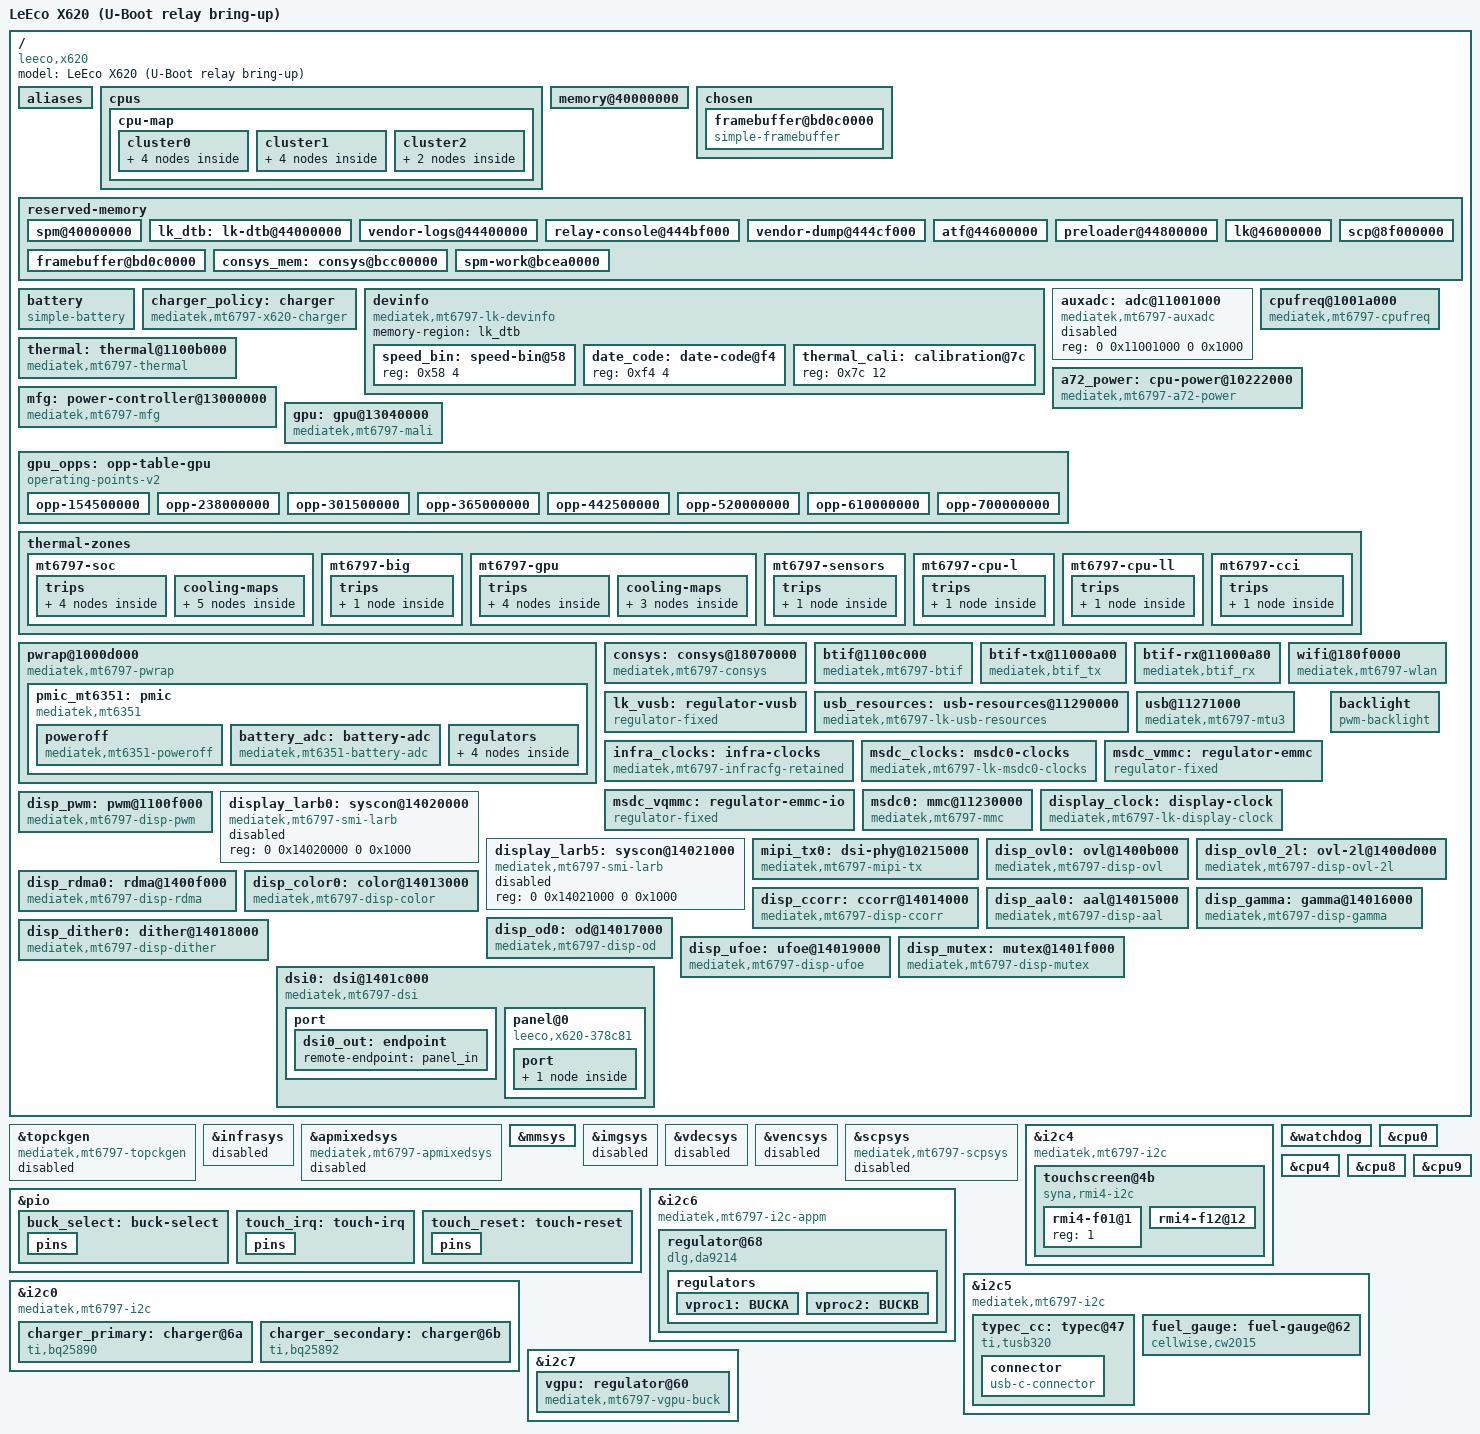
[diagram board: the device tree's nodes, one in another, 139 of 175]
// SPDX-License-Identifier: GPL-2.0-only
/dts-v1/;
#include "mt6797.dtsi"
#include <dt-bindings/clock/mt6797-clk.h>
#include <dt-bindings/gpio/gpio.h>
#include <dt-bindings/thermal/thermal.h>

/ {
	model = "LeEco X620 (U-Boot relay bring-up)";
	compatible = "leeco,x620", "mediatek,mt6797";
	aliases {
		mmc0 = &msdc0;
		i2c0 = &i2c0;
		i2c5 = &i2c5;
		i2c4 = &i2c4;
		i2c6 = &i2c6;
		i2c7 = &i2c7;
		ovl0 = &disp_ovl0;
		ovl-2l0 = &disp_ovl0_2l;
		rdma0 = &disp_rdma0;
		dsi0 = &dsi0;
		mutex0 = &disp_mutex;
	};
	cpus {
		cpu-map {
			cluster0 {
				core0 { cpu = <&cpu0>; };
				core1 { cpu = <&cpu1>; };
				core2 { cpu = <&cpu2>; };
				core3 { cpu = <&cpu3>; };
			};
			cluster1 {
				core0 { cpu = <&cpu4>; };
				core1 { cpu = <&cpu5>; };
				core2 { cpu = <&cpu6>; };
				core3 { cpu = <&cpu7>; };
			};
			cluster2 {
				core0 { cpu = <&cpu8>; };
				core1 { cpu = <&cpu9>; };
			};
		};
	};
	memory@40000000 {
		device_type = "memory";
		/* LK-populated banks from the live stock DT; firmware holes stay excluded. */
		reg = <0 0x40000000 0 0x4e000000>,
		      <0 0x8e600000 0 0x11a00000>,
		      <0 0xa0000000 0 0x12000000>,
		      <0 0xb9000000 0 0x03000000>,
		      <0 0xbcc00000 0 0x002c0000>,
		      <0 0xc0000000 0 0x40000000>;
	};
	chosen {
		#address-cells = <2>;
		#size-cells = <2>;
		ranges;
		bootargs = "console=tty0 earlycon=mt6797ram,mmio32,0x444bf000 keep_bootcon loglevel=8 ignore_loglevel printk.time=1 clk_ignore_unused pd_ignore_unused maxcpus=1 cpuidle.off=1 rdinit=/init panic=0 fsck.mode=skip fbcon=nodefer";
		framebuffer@bd0c0000 {
			compatible = "simple-framebuffer";
			reg = <0 0xbd0c0000 0 0x7f8000>;
			width = <1080>;
			height = <1920>;
			stride = <4352>;
			format = "x8r8g8b8";
		};
	};
	reserved-memory {
		#address-cells = <2>;
		#size-cells = <2>;
		ranges;
		spm@40000000 { reg = <0 0x40000000 0 0x1000>; no-map; };
		lk_dtb: lk-dtb@44000000 { reg = <0 0x44000000 0 0x400000>; no-map; };
		vendor-logs@44400000 { reg = <0 0x44400000 0 0xbf000>; no-map; };
		/* Raw persistent console is read by stock TWRP; not owned by ramoops. */
		relay-console@444bf000 { reg = <0 0x444bf000 0 0x10000>; no-map; };
		vendor-dump@444cf000 { reg = <0 0x444cf000 0 0x31000>; no-map; };
		atf@44600000 { reg = <0 0x44600000 0 0x70000>; no-map; };
		preloader@44800000 { reg = <0 0x44800000 0 0x100000>; no-map; };
		lk@46000000 { reg = <0 0x46000000 0 0x400000>; no-map; };
		framebuffer@bd0c0000 { reg = <0 0xbd0c0000 0 0x1be0000>; no-map; };
		/* Stock /proc/iomem fixes the dynamic SCP/CONSYS/SPM allocations here. */
		scp@8f000000 { reg = <0 0x8f000000 0 0x1000000>; no-map; };
		consys_mem: consys@bcc00000 { reg = <0 0xbcc00000 0 0x200000>; no-map; };
		spm-work@bcea0000 { reg = <0 0xbcea0000 0 0x16000>; no-map; };
	};


	battery: battery {
		compatible = "simple-battery";
		device-chemistry = "lithium-ion";
		charge-full-design-microamp-hours = <3000000>;
		voltage-min-design-microvolt = <3400000>;
		voltage-max-design-microvolt = <4400000>;
		constant-charge-current-max-microamp = <1500000>;
		constant-charge-voltage-max-microvolt = <4400000>;
		charge-term-current-microamp = <150000>;
	};

	charger_policy: charger {
		compatible = "mediatek,mt6797-x620-charger";
		primary-charger = <&charger_primary>;
		secondary-charger = <&charger_secondary>;
		battery-gauge = <&fuel_gauge>;
		typec-current-source = <&typec_cc>;
		power-supplies = <&typec_cc>;
		#cooling-cells = <2>;
	};

	devinfo: devinfo {
		compatible = "mediatek,mt6797-lk-devinfo";
		memory-region = <&lk_dtb>;
		#address-cells = <1>;
		#size-cells = <1>;
		speed_bin: speed-bin@58 { reg = <0x58 4>; };
		date_code: date-code@f4 { reg = <0xf4 4>; };
		thermal_cali: calibration@7c { reg = <0x7c 12>; };
	};

	auxadc: adc@11001000 {
		compatible = "mediatek,mt6797-auxadc";
		reg = <0 0x11001000 0 0x1000>;
		status = "disabled"; /* Channel 11 is owned by the thermal controller. */
	};

	thermal: thermal@1100b000 {
		compatible = "mediatek,mt6797-thermal";
		reg = <0 0x1100b000 0 0x1000>;
		clocks = <&infra_clocks CLK_INFRA_THERM>, <&infra_clocks CLK_INFRA_AUXADC>;
		clock-names = "therm", "auxadc";
		mediatek,auxadc = <&auxadc>;
		mediatek,apmixedsys = <&apmixedsys>;
		mediatek,infracfg = <&infrasys>;
		nvmem-cells = <&thermal_cali>;
		nvmem-cell-names = "calibration";
		#thermal-sensor-cells = <1>;
	};

	cpufreq@1001a000 {
		compatible = "mediatek,mt6797-cpufreq";
		reg = <0 0x1001a000 0 0x1000>,
		      <0 0x11015000 0 0x1000>,
		      <0 0x10220000 0 0x1000>;
		mediatek,infracfg = <&infrasys>;
		mediatek,topckgen = <&topckgen>;
		vproc-supply = <&vproc1>;
		nvmem-cells = <&speed_bin>, <&date_code>;
		nvmem-cell-names = "speed-bin", "date-code";
	};

	a72_power: cpu-power@10222000 {
		compatible = "mediatek,mt6797-a72-power";
		reg = <0 0x10222000 0 0x1000>,
		      <0 0x10006000 0 0x1000>;
		reg-names = "mcucfg2", "spm";
		vproc-supply = <&vproc2>;
		resets = <&watchdog 11>;
		reset-names = "pwrap-spi";
	};

	mfg: power-controller@13000000 {
		compatible = "mediatek,mt6797-mfg";
		reg = <0 0x13000000 0 0x1000>;
		mediatek,spm = <&scpsys>;
		mediatek,infracfg = <&infrasys>;
		mediatek,topckgen = <&topckgen>;
		mediatek,apmixedsys = <&apmixedsys>;
		mali-supply = <&vgpu>;
		operating-points-v2 = <&gpu_opps>;
		resets = <&watchdog 2>;
		#clock-cells = <0>;
		#power-domain-cells = <0>;
	};

	gpu: gpu@13040000 {
		compatible = "mediatek,mt6797-mali", "arm,mali-t880";
		reg = <0 0x13040000 0 0x4000>;
		interrupts = <GIC_SPI 264 IRQ_TYPE_LEVEL_LOW>,
			     <GIC_SPI 263 IRQ_TYPE_LEVEL_LOW>,
			     <GIC_SPI 262 IRQ_TYPE_LEVEL_LOW>;
		interrupt-names = "job", "mmu", "gpu";
		clocks = <&mfg>;
		clock-names = "core";
		power-domains = <&mfg>;
		/* MFG owns voltage changes, including the 416 MHz divider-change bridge. */
		operating-points-v2 = <&gpu_opps>;
		#cooling-cells = <2>;
		/* Factory dynamic-power reference: 1169 mW at 800 MHz / 1 V. */
		dynamic-power-coefficient = <1461>;
	};

	gpu_opps: opp-table-gpu {
		compatible = "operating-points-v2";
		/* Factory FY table, rounded to its FAN53555 VSEL0 selectors. */
		opp-154500000 { opp-hz = /bits/ 64 <154500000>; opp-microvolt = <808216>; };
		opp-238000000 { opp-hz = /bits/ 64 <238000000>; opp-microvolt = <859520>; };
		opp-301500000 { opp-hz = /bits/ 64 <301500000>; opp-microvolt = <897998>; };
		opp-365000000 { opp-hz = /bits/ 64 <365000000>; opp-microvolt = <910824>; };
		opp-442500000 { opp-hz = /bits/ 64 <442500000>; opp-microvolt = <974954>; };
		opp-520000000 { opp-hz = /bits/ 64 <520000000>; opp-microvolt = <1000606>; };
		opp-610000000 { opp-hz = /bits/ 64 <610000000>; opp-microvolt = <1077562>; };
		opp-700000000 { opp-hz = /bits/ 64 <700000000>; opp-microvolt = <1128866>; };
	};

	thermal-zones {
		/* Stock TZCPU thresholds; cooling states use mainline cpufreq. */
		mt6797-soc {
			polling-delay = <250>;
			polling-delay-passive = <40>;
			thermal-sensors = <&thermal 6>;
			trips {
				soc_warm: warm { temperature = <65000>; hysteresis = <2000>; type = "passive"; };
				soc_hot: hot { temperature = <85000>; hysteresis = <2000>; type = "passive"; };
				soc_very_hot: very-hot { temperature = <95000>; hysteresis = <2000>; type = "passive"; };
				critical { temperature = <117000>; hysteresis = <0>; type = "critical"; };
			};
			cooling-maps {
				map-charge-warm { trip = <&soc_warm>; cooling-device = <&charger_policy 1 2>; };
				map-charge-hot { trip = <&soc_hot>; cooling-device = <&charger_policy 3 3>; };
				map-warm { trip = <&soc_warm>; cooling-device = <&cpu0 THERMAL_NO_LIMIT THERMAL_NO_LIMIT>, <&cpu4 THERMAL_NO_LIMIT THERMAL_NO_LIMIT>, <&cpu8 THERMAL_NO_LIMIT THERMAL_NO_LIMIT>, <&cpu9 THERMAL_NO_LIMIT THERMAL_NO_LIMIT>, <&gpu THERMAL_NO_LIMIT THERMAL_NO_LIMIT>; };
				map-hot { trip = <&soc_hot>; cooling-device = <&cpu0 3 THERMAL_NO_LIMIT>, <&cpu4 3 THERMAL_NO_LIMIT>, <&cpu8 3 THERMAL_NO_LIMIT>, <&cpu9 3 THERMAL_NO_LIMIT>, <&gpu 3 THERMAL_NO_LIMIT>; };
				map-very-hot { trip = <&soc_very_hot>; cooling-device = <&cpu0 12 THERMAL_NO_LIMIT>, <&cpu4 12 THERMAL_NO_LIMIT>, <&cpu8 12 THERMAL_NO_LIMIT>, <&cpu9 12 THERMAL_NO_LIMIT>, <&gpu 6 THERMAL_NO_LIMIT>; };
			};
		};
		mt6797-big { polling-delay = <1000>; polling-delay-passive = <0>; thermal-sensors = <&thermal 0>; trips { critical { temperature = <117000>; hysteresis = <0>; type = "critical"; }; }; };
		mt6797-gpu {
			polling-delay = <250>;
			polling-delay-passive = <40>;
			thermal-sensors = <&thermal 1>;
			trips {
				gpu_warm: warm { temperature = <65000>; hysteresis = <2000>; type = "passive"; };
				gpu_hot: hot { temperature = <85000>; hysteresis = <2000>; type = "passive"; };
				gpu_very_hot: very-hot { temperature = <95000>; hysteresis = <2000>; type = "passive"; };
				critical { temperature = <117000>; hysteresis = <0>; type = "critical"; };
			};
			cooling-maps {
				map-warm { trip = <&gpu_warm>; cooling-device = <&gpu THERMAL_NO_LIMIT THERMAL_NO_LIMIT>; };
				map-hot { trip = <&gpu_hot>; cooling-device = <&gpu 3 THERMAL_NO_LIMIT>; };
				map-very-hot { trip = <&gpu_very_hot>; cooling-device = <&gpu 6 THERMAL_NO_LIMIT>; };
			};
		};
		mt6797-sensors { polling-delay = <1000>; polling-delay-passive = <0>; thermal-sensors = <&thermal 2>; trips { critical { temperature = <117000>; hysteresis = <0>; type = "critical"; }; }; };
		mt6797-cpu-l { polling-delay = <1000>; polling-delay-passive = <0>; thermal-sensors = <&thermal 3>; trips { critical { temperature = <117000>; hysteresis = <0>; type = "critical"; }; }; };
		mt6797-cpu-ll { polling-delay = <1000>; polling-delay-passive = <0>; thermal-sensors = <&thermal 4>; trips { critical { temperature = <117000>; hysteresis = <0>; type = "critical"; }; }; };
		mt6797-cci { polling-delay = <1000>; polling-delay-passive = <0>; thermal-sensors = <&thermal 5>; trips { critical { temperature = <117000>; hysteresis = <0>; type = "critical"; }; }; };
	};


	pwrap@1000d000 {
		compatible = "mediatek,mt6797-pwrap";
		reg = <0 0x1000d000 0 0x1000>;
		reg-names = "pwrap";
		interrupts = <GIC_SPI 178 IRQ_TYPE_LEVEL_HIGH>;
		mediatek,retain-bootloader-state;
		pmic_mt6351: pmic {
			compatible = "mediatek,mt6351";
			poweroff {
				compatible = "mediatek,mt6351-poweroff";
			};
			battery_adc: battery-adc {
				compatible = "mediatek,mt6351-battery-adc";
				#io-channel-cells = <1>;
				/* Live stock bat_metter: Rfg=10, CAR_TUNE=118, 24k/2.8V NTC. */
				mediatek,sense-resistor-milliohm = <10>;
				mediatek,car-tune-percent = <118>;
				mediatek,ntc-pullup-ohms = <24000>;
				mediatek,ntc-pullup-millivolt = <2800>;
			};
			regulators {
				vcn18: ldo_vcn18 {
					regulator-name = "vcn18";
					regulator-min-microvolt = <1800000>;
					regulator-max-microvolt = <1800000>;
				};
				vcn28: ldo_vcn28 {
					regulator-name = "vcn28";
					regulator-min-microvolt = <2800000>;
					regulator-max-microvolt = <2800000>;
				};
				vcn33_bt: ldo_vcn33_bt {
					regulator-name = "vcn33_bt";
					regulator-min-microvolt = <3300000>;
					regulator-max-microvolt = <3300000>;
				};
				vcn33_wifi: ldo_vcn33_wifi {
					regulator-name = "vcn33_wifi";
					regulator-min-microvolt = <3300000>;
					regulator-max-microvolt = <3300000>;
				};
			};
		};
	};
	consys: consys@18070000 {
		compatible = "mediatek,mt6797-consys";
		reg = <0 0x18070000 0 0x200>, <0 0x10007000 0 0x100>,
		      <0 0x10000000 0 0x2000>, <0 0x10006000 0 0x1000>;
		interrupts = <GIC_SPI 284 IRQ_TYPE_LEVEL_LOW>,
			     <GIC_SPI 285 IRQ_TYPE_LEVEL_LOW>;
		memory-region = <&consys_mem>;
		vcn18-supply = <&vcn18>;
		vcn28-supply = <&vcn28>;
		vcn33_bt-supply = <&vcn33_bt>;
		vcn33_wifi-supply = <&vcn33_wifi>;
		/* Stock WMT_SOC.cfg: gps_lna_enable=0, co_clock_flag=0. */
		mediatek,no-gps-lna;
		clocks = <&infra_clocks CLK_INFRA_BTIF>, <&infra_clocks CLK_INFRA_AP_DMA>;
		clock-names = "btifc", "apdmac";
	};
	btif@1100c000 {
		compatible = "mediatek,mt6797-btif", "mediatek,btif";
		reg = <0 0x1100c000 0 0x1000>;
		interrupts = <GIC_SPI 130 IRQ_TYPE_LEVEL_LOW>;
		clocks = <&infra_clocks CLK_INFRA_BTIF>, <&infra_clocks CLK_INFRA_AP_DMA>;
		clock-names = "btifc", "apdmac";
	};
	btif-tx@11000a00 {
		compatible = "mediatek,btif_tx";
		reg = <0 0x11000a00 0 0x80>;
		interrupts = <GIC_SPI 116 IRQ_TYPE_LEVEL_LOW>;
	};
	btif-rx@11000a80 {
		compatible = "mediatek,btif_rx";
		reg = <0 0x11000a80 0 0x80>;
		interrupts = <GIC_SPI 117 IRQ_TYPE_LEVEL_LOW>;
	};
	wifi@180f0000 {
		compatible = "mediatek,mt6797-wlan", "mediatek,WIFI";
		reg = <0 0x180f0000 0 0x1100>;
		interrupts = <GIC_SPI 283 IRQ_TYPE_LEVEL_LOW>;
		clocks = <&infra_clocks CLK_INFRA_AP_DMA>;
		clock-names = "wifi-dma";
	};
	lk_vusb: regulator-vusb {
		compatible = "regulator-fixed";
		regulator-name = "lk-retained-vusb33";
		regulator-min-microvolt = <3300000>;
		regulator-max-microvolt = <3300000>;
		regulator-always-on;
	};
	usb_resources: usb-resources@11290000 {
		compatible = "mediatek,mt6797-lk-usb-resources", "leeco,x620-lk-usb-resources";
		reg = <0 0x11290000 0 0x1000>, <0 0x10001000 0 0x1000>;
		reg-names = "phy", "infracfg";
		#phy-cells = <0>;
		#clock-cells = <1>;
	};
	usb@11271000 {
		compatible = "mediatek,mt6797-mtu3", "mediatek,mtu3";
		/* Linux offsets start at the device block, unlike U-Boot's xHCI base. */
		reg = <0 0x11271000 0 0x3000>, <0 0x11280700 0 0x100>;
		reg-names = "mac", "ippc";
		/* Live vendor DT: device SPI 127, host SPI 126. */
		interrupts = <GIC_SPI 127 IRQ_TYPE_LEVEL_LOW>;
		interrupt-names = "device";
		clocks = <&usb_resources 1>, <&usb_resources 2>,
			 <&usb_resources 0>, <&usb_resources 0>;
		clock-names = "sys_ck", "ref_ck", "mcu_ck", "dma_ck";
		phys = <&usb_resources>;
		vusb33-supply = <&lk_vusb>;
		dr_mode = "peripheral";
		maximum-speed = "high-speed";
		mediatek,u3p-dis-msk = <1>;
		mediatek,force-vbus;
	};

	infra_clocks: infra-clocks {
		compatible = "mediatek,mt6797-infracfg-retained";
		#clock-cells = <1>;
		mediatek,topckgen = <&topckgen>;
		mediatek,infracfg = <&infrasys>;
		mediatek,apmixedsys = <&apmixedsys>;
	};

	msdc_clocks: msdc0-clocks {
		compatible = "mediatek,mt6797-lk-msdc0-clocks", "leeco,x620-msdc0-clocks";
		#clock-cells = <1>;
		mediatek,topckgen = <&topckgen>;
		mediatek,infracfg = <&infrasys>;
		mediatek,apmixedsys = <&apmixedsys>;
		mediatek,high-speed;
	};
	msdc_vmmc: regulator-emmc {
		compatible = "regulator-fixed";
		regulator-name = "lk-retained-vemc";
		regulator-min-microvolt = <3000000>;
		regulator-max-microvolt = <3000000>;
		regulator-always-on;
	};
	msdc_vqmmc: regulator-emmc-io {
		compatible = "regulator-fixed";
		regulator-name = "lk-retained-emmc-io";
		regulator-min-microvolt = <1800000>;
		regulator-max-microvolt = <1800000>;
		regulator-always-on;
	};
	msdc0: mmc@11230000 {
		compatible = "mediatek,mt6797-mmc";
		reg = <0 0x11230000 0 0x1000>;
		interrupts = <GIC_SPI 79 IRQ_TYPE_LEVEL_LOW>;
		clocks = <&msdc_clocks 0>, <&msdc_clocks 1>, <&msdc_clocks 2>;
		clock-names = "source", "hclk", "source_cg";
		/* Empty states preserve the working pinmux/drive settings from LK. */
		pinctrl-names = "default", "state_uhs";
		pinctrl-0 = <>;
		pinctrl-1 = <>;
		vmmc-supply = <&msdc_vmmc>;
		vqmmc-supply = <&msdc_vqmmc>;
		bus-width = <8>;
		max-frequency = <200000000>;
		cap-mmc-highspeed;
		mmc-hs200-1_8v;
		mmc-hs400-1_8v;
		mediatek,tuning-step = <64>;
		mediatek,latch-ck = <1>;
		/* MT6797 autok uses coarse DS delay 20 and scans the fine delays. */
		mediatek,hs400-ds-dly3 = <20>;
		non-removable;
		no-sd;
		no-sdio;
	};

	display_clock: display-clock {
		compatible = "mediatek,mt6797-lk-display-clock", "leeco,x620-display-clock";
		#clock-cells = <1>;
		mediatek,topckgen = <&topckgen>;
		mediatek,apmixedsys = <&apmixedsys>;
	};
	disp_pwm: pwm@1100f000 {
		compatible = "mediatek,mt6797-disp-pwm";
		reg = <0 0x1100f000 0 0x1000>;
		#pwm-cells = <2>;
		clocks = <&display_clock 1>, <&infra_clocks CLK_INFRA_DISP_PWM>;
		clock-names = "main", "mm";
	};

	backlight: backlight {
		compatible = "pwm-backlight";
		/* Stock: 26 MHz, divider 0, 1024 ticks per period (~25.39 kHz). */
		pwms = <&disp_pwm 0 39385>;
		brightness-levels = <0 1023>;
		num-interpolated-steps = <1023>;
		default-brightness-level = <512>;
	};

	display_larb0: syscon@14020000 {
		compatible = "mediatek,mt6797-smi-larb", "syscon";
		reg = <0 0x14020000 0 0x1000>;
		status = "disabled";
	};
	display_larb5: syscon@14021000 {
		compatible = "mediatek,mt6797-smi-larb", "syscon";
		reg = <0 0x14021000 0 0x1000>;
		status = "disabled";
	};
	mipi_tx0: dsi-phy@10215000 {
		compatible = "mediatek,mt6797-mipi-tx";
		reg = <0 0x10215000 0 0x1000>;
		clocks = <&clk26m>;
		clock-output-names = "mt6797-mipi-tx0";
		#clock-cells = <0>;
		#phy-cells = <0>;
	};
	disp_ovl0: ovl@1400b000 {
		compatible = "mediatek,mt6797-disp-ovl";
		reg = <0 0x1400b000 0 0x1000>;
		interrupts = <GIC_SPI 213 IRQ_TYPE_LEVEL_LOW>;
		clocks = <&mmsys CLK_MM_DISP_OVL0>;
	};
	disp_ovl0_2l: ovl-2l@1400d000 {
		compatible = "mediatek,mt6797-disp-ovl-2l";
		reg = <0 0x1400d000 0 0x1000>;
		interrupts = <GIC_SPI 215 IRQ_TYPE_LEVEL_LOW>;
		clocks = <&mmsys CLK_MM_DISP_OVL0_2L>;
	};
	disp_rdma0: rdma@1400f000 {
		compatible = "mediatek,mt6797-disp-rdma";
		reg = <0 0x1400f000 0 0x1000>;
		interrupts = <GIC_SPI 217 IRQ_TYPE_LEVEL_LOW>;
		clocks = <&mmsys CLK_MM_DISP_RDMA0>;
	};
	disp_color0: color@14013000 {
		compatible = "mediatek,mt6797-disp-color";
		reg = <0 0x14013000 0 0x1000>;
		interrupts = <GIC_SPI 221 IRQ_TYPE_LEVEL_LOW>;
		clocks = <&mmsys CLK_MM_DISP_COLOR>;
	};
	disp_ccorr: ccorr@14014000 {
		compatible = "mediatek,mt6797-disp-ccorr";
		reg = <0 0x14014000 0 0x1000>;
		interrupts = <GIC_SPI 222 IRQ_TYPE_LEVEL_LOW>;
		clocks = <&mmsys CLK_MM_DISP_CCORR>;
	};
	disp_aal0: aal@14015000 {
		compatible = "mediatek,mt6797-disp-aal";
		reg = <0 0x14015000 0 0x1000>;
		interrupts = <GIC_SPI 223 IRQ_TYPE_LEVEL_LOW>;
		clocks = <&mmsys CLK_MM_DISP_AAL>;
	};
	disp_gamma: gamma@14016000 {
		compatible = "mediatek,mt6797-disp-gamma";
		reg = <0 0x14016000 0 0x1000>;
		interrupts = <GIC_SPI 224 IRQ_TYPE_LEVEL_LOW>;
		clocks = <&mmsys CLK_MM_DISP_GAMMA>;
	};
	disp_od0: od@14017000 {
		compatible = "mediatek,mt6797-disp-od";
		reg = <0 0x14017000 0 0x1000>;
		interrupts = <GIC_SPI 225 IRQ_TYPE_LEVEL_LOW>;
		clocks = <&mmsys CLK_MM_DISP_OD>;
	};
	disp_dither0: dither@14018000 {
		compatible = "mediatek,mt6797-disp-dither";
		reg = <0 0x14018000 0 0x1000>;
		interrupts = <GIC_SPI 226 IRQ_TYPE_LEVEL_LOW>;
		clocks = <&mmsys CLK_MM_DISP_DITHER>;
	};
	disp_ufoe: ufoe@14019000 {
		compatible = "mediatek,mt6797-disp-ufoe";
		reg = <0 0x14019000 0 0x1000>;
		interrupts = <GIC_SPI 227 IRQ_TYPE_LEVEL_LOW>;
		clocks = <&mmsys CLK_MM_DISP_UFOE>;
	};
	disp_mutex: mutex@1401f000 {
		compatible = "mediatek,mt6797-disp-mutex";
		reg = <0 0x1401f000 0 0x1000>;
		interrupts = <GIC_SPI 202 IRQ_TYPE_LEVEL_LOW>;
	};
	dsi0: dsi@1401c000 {
		compatible = "mediatek,mt6797-dsi";
		reg = <0 0x1401c000 0 0x1000>;
		interrupts = <GIC_SPI 229 IRQ_TYPE_LEVEL_LOW>;
		clocks = <&mmsys CLK_MM_DSI0_MM_CLOCK>,
			 <&mmsys CLK_MM_DSI0_INTERFACE_CLOCK>, <&mipi_tx0>;
		clock-names = "engine", "digital", "hs";
		phys = <&mipi_tx0>;
		phy-names = "dphy";
		#address-cells = <1>;
		#size-cells = <0>;
		port {
			dsi0_out: endpoint { remote-endpoint = <&panel_in>; };
		};
		panel@0 {
			compatible = "leeco,x620-378c81";
			backlight = <&backlight>;
			reg = <0>;
			mediatek,mmsys = <&mmsys>;
			port {
				panel_in: endpoint { remote-endpoint = <&dsi0_out>; };
			};
		};
	};
};

/* Retain firmware clocks except the isolated MSDC0 clock provider above. */
&topckgen {
	compatible = "mediatek,mt6797-topckgen", "syscon";
	status = "disabled";
};
&infrasys { status = "disabled"; };
&apmixedsys {
	compatible = "mediatek,mt6797-apmixedsys", "syscon";
	status = "disabled";
};
&mmsys {
	status = "okay";
	clocks = <&display_clock 0>;
	clock-names = "mm";
	mediatek,larb0 = <&display_larb0>;
	mediatek,larb5 = <&display_larb5>;
};
&imgsys { status = "disabled"; };
&vdecsys { status = "disabled"; };
&vencsys { status = "disabled"; };
&scpsys {
	compatible = "mediatek,mt6797-scpsys", "syscon";
	/delete-property/ clocks;
	/delete-property/ clock-names;
	status = "disabled";
};
&pio {
	reg = <0 0x10005000 0 0x1000>,
	      <0 0x10002000 0 0x400>,
	      <0 0x10002400 0 0x400>,
	      <0 0x10002800 0 0x400>,
	      <0 0x10002c00 0 0x400>,
	      <0 0x1000b000 0 0x1000>;
	reg-names = "gpio", "iocfgl", "iocfgb", "iocfgr", "iocfgt", "eint";
	interrupts = <GIC_SPI 170 IRQ_TYPE_LEVEL_HIGH>;
	interrupt-controller;
	#interrupt-cells = <2>;
	status = "okay";

	buck_select: buck-select {
		pins {
			pinmux = <MT6797_GPIO61__FUNC_GPIO61>;
			output-low;
			bias-disable;
			input-schmitt-disable;
		};
	};

	touch_irq: touch-irq {
		pins {
			pinmux = <MT6797_GPIO68__FUNC_EINT7>;
			input-enable;
			bias-pull-down;
		};
	};

	touch_reset: touch-reset {
		pins {
			pinmux = <MT6797_GPIO57__FUNC_GPIO57>;
			output-high;
		};
	};
};

&i2c4 {
	compatible = "mediatek,mt6797-i2c";
	clocks = <&infra_clocks CLK_INFRA_I2C4>, <&infra_clocks CLK_INFRA_AP_DMA>;
	clock-names = "main", "dma";
	clock-frequency = <400000>;
	clock-div = <10>;
	pinctrl-names = "default";
	pinctrl-0 = <&i2c4_pins_a>;
	status = "okay";

	touchscreen@4b {
		compatible = "syna,rmi4-i2c";
		reg = <0x4b>;
		interrupt-parent = <&pio>;
		/* Stock EIC maps GPIO68 to EINT7, with falling-edge attention. */
		interrupts = <7 IRQ_TYPE_EDGE_FALLING>;
		reset-gpios = <&pio 57 GPIO_ACTIVE_LOW>;
		pinctrl-names = "default";
		pinctrl-0 = <&touch_irq>, <&touch_reset>;
		/* Active stock Synaptics v61: 200ms ready, 20ms reset pulse. */
		syna,startup-delay-ms = <200>;
		syna,reset-delay-ms = <200>;
		#address-cells = <1>;
		#size-cells = <0>;

		rmi4-f01@1 {
			reg = <1>;
		};

		rmi4-f12@12 {
			reg = <0x12>;
			syna,sensor-type = <1>;
		};
	};
};

&watchdog { #reset-cells = <1>; };


/* Both active A53 clusters share VPROC1 and eight SRAM LDOs. */
&cpu0 { #cooling-cells = <2>; };
&cpu4 { #cooling-cells = <2>; };
&cpu8 { #cooling-cells = <2>; };
&cpu9 { #cooling-cells = <2>; };

&i2c6 {
	compatible = "mediatek,mt6797-i2c-appm";
	clocks = <&infra_clocks CLK_INFRA_I2C_APPM>, <&infra_clocks CLK_INFRA_AP_DMA>;
	clock-names = "main", "dma";
	clock-frequency = <3400000>;
	clock-div = <10>;
	pinctrl-names = "default";
	pinctrl-0 = <&i2c6_pins_a>;
	mediatek,use-push-pull;
	status = "okay";

	regulator@68 {
		compatible = "dlg,da9214";
		reg = <0x68>;
		pinctrl-names = "default";
		pinctrl-0 = <&buck_select>;
		regulators {
			vproc1: BUCKA {
				regulator-name = "vproc1";
				regulator-min-microvolt = <770000>;
				regulator-max-microvolt = <1200000>;
				regulator-boot-on;
				regulator-always-on;
			};
			vproc2: BUCKB {
				regulator-name = "vproc2";
				regulator-min-microvolt = <800000>;
				regulator-max-microvolt = <1200000>;
			};
		};
	};
};

/* Stock runtime logs identify BQ25890 (PN=3), BQ25892 (PN=0, rev=1), CW2015 at 5-0062.
 * Poll both chargers until the board's EIC interrupt routing is verified.
 */
&i2c0 {
	compatible = "mediatek,mt6797-i2c";
	clocks = <&infra_clocks CLK_INFRA_I2C0>, <&infra_clocks CLK_INFRA_AP_DMA>;
	clock-names = "main", "dma";
	clock-frequency = <100000>;
	clock-div = <10>;
	pinctrl-names = "default";
	pinctrl-0 = <&i2c0_pins_a>;
	status = "okay";

	charger_primary: charger@6a {
		compatible = "ti,bq25890";
		reg = <0x6a>;
		monitored-battery = <&battery>;
		ti,charge-current = <1500000>;
		ti,battery-regulation-voltage = <4400000>;
		ti,termination-current = <150000>;
		ti,precharge-current = <128000>;
		ti,minimum-sys-voltage = <3500000>;
		ti,boost-voltage = <4998000>;
		ti,boost-max-current = <1400000>;
		ti,thermal-regulation-threshold = <120>;
		ti,disable-high-voltage;
		ti,watchdog-timeout-ms = <40000>;
		linux,skip-reset;
		linux,initial-charge-inhibit;
		linux,poll-interval-ms = <2000>;
	};

	charger_secondary: charger@6b {
		compatible = "ti,bq25892";
		reg = <0x6b>;
		monitored-battery = <&battery>;
		ti,charge-current = <1500000>;
		ti,battery-regulation-voltage = <4400000>;
		ti,termination-current = <150000>;
		ti,precharge-current = <128000>;
		ti,minimum-sys-voltage = <3500000>;
		ti,boost-voltage = <4998000>;
		ti,boost-max-current = <1400000>;
		ti,thermal-regulation-threshold = <120>;
		ti,disable-high-voltage;
		linux,skip-reset;
		linux,initial-charge-inhibit;
		linux,initial-hiz;
		linux,poll-interval-ms = <2000>;
	};
};

&i2c5 {
	compatible = "mediatek,mt6797-i2c";
	clocks = <&infra_clocks CLK_INFRA_I2C5>, <&infra_clocks CLK_INFRA_AP_DMA>;
	clock-names = "main", "dma";
	clock-frequency = <100000>;
	clock-div = <10>;
	pinctrl-names = "default";
	pinctrl-0 = <&i2c5_pins_a>;
	status = "okay";

	typec_cc: typec@47 {
		compatible = "ti,tusb320";
		reg = <0x47>;
		/* Retain the stock PORT-pin/DRP setup; do not detach an active source. */
		linux,skip-reset;
		linux,poll-interval-ms = <100>;
		connector {
			compatible = "usb-c-connector";
			label = "USB-C";
			power-role = "sink";
			data-role = "device";
			typec-power-opmode = "default";
		};
	};

	fuel_gauge: fuel-gauge@62 {
		compatible = "cellwise,cw2015";
		reg = <0x62>;
		monitored-battery = <&battery>;
		power-supplies = <&charger_primary>;
		/* Keep the factory-programmed CW2015 battery profile. */
		cellwise,monitor-interval-ms = <5000>;
		io-channels = <&battery_adc 0>, <&battery_adc 2>;
		io-channel-names = "current", "temperature";
	};
};

&i2c7 {
	clocks = <&infra_clocks CLK_INFRA_I2C_GPUPM>,
		 <&infra_clocks CLK_INFRA_AP_DMA>;
	clock-names = "main", "dma";
	clock-frequency = <400000>;
	clock-div = <10>;
	pinctrl-names = "default";
	pinctrl-0 = <&i2c7_pins_a>;
	status = "okay";

	vgpu: regulator@60 {
		compatible = "mediatek,mt6797-vgpu-buck", "fcs,fan53555";
		reg = <0x60>;
		regulator-name = "vgpu";
		regulator-min-microvolt = <603000>;
		regulator-max-microvolt = <1128900>;
		regulator-ramp-delay = <32000>;
		fcs,suspend-voltage-selector = <1>;
	};
};
